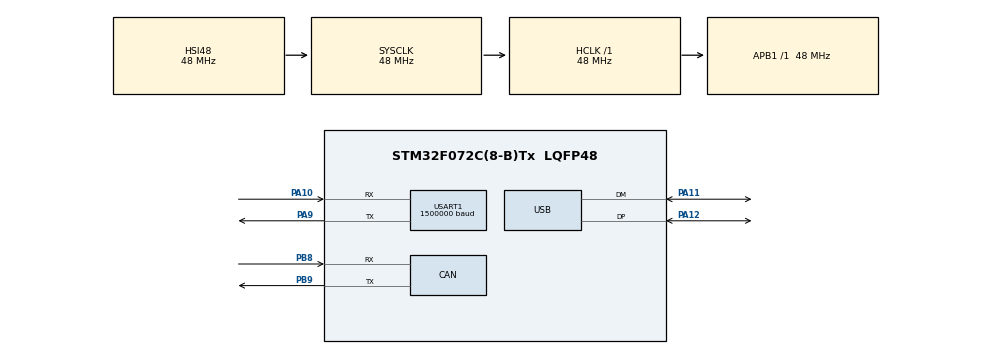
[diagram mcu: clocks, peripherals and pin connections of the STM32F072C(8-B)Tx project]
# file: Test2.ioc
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CAN.CalculateTimeQuantum=333.3333333333333
Mcu.Family=STM32F0
Mcu.Name=STM32F072C(8-B)Tx
Mcu.Package=LQFP48
NVIC.USB_IRQn=true\:0\:0\:false\:false\:true\:false\:true
PA10.Mode=Asynchronous
PA10.Signal=USART1_RX
PA11.Mode=Device
PA11.Signal=USB_DM
PA12.Mode=Device
PA12.Signal=USB_DP
PA9.Mode=Asynchronous
PA9.Signal=USART1_TX
PB8.Mode=Master
PB8.Signal=CAN_RX
PB9.Mode=Master
PB9.Signal=CAN_TX
ProjectManager.HeapSize=0x200
ProjectManager.StackSize=0x400
ProjectManager.TargetToolchain=STM32CubeIDE
RCC.AHBFreq_Value=48000000
RCC.APB1Freq_Value=48000000
RCC.APB1TimFreq_Value=48000000
RCC.HCLKFreq_Value=48000000
RCC.SYSCLKFreq_VALUE=48000000
RCC.SYSCLKSource=RCC_SYSCLKSOURCE_HSI48
USART1.BaudRate=1500000
USART1.VirtualMode-Asynchronous=VM_ASYNC
USB_DEVICE.CLASS_NAME_FS=HID
USB_DEVICE.PID_HID_FS=0x572c
USB_DEVICE.VID=0x483
USB_DEVICE.VirtualMode=Hid
USB_DEVICE.VirtualModeFS=Hid_FS
VP_USB_DEVICE_VS_USB_DEVICE_HID_FS.Mode=HID_FS
board=custom

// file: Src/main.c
/* USER CODE BEGIN Header */
/**
  ******************************************************************************
  * @file           : main.c
  * @brief          : Main program body
  ******************************************************************************
  * @attention
  *
  * <h2><center>&copy; Copyright (c) 2019 STMicroelectronics.
  * All rights reserved.</center></h2>
  *
  * This software component is licensed by ST under BSD 3-Clause license,
  * the "License"; You may not use this file except in compliance with the
  * License. You may obtain a copy of the License at:
  *                        opensource.org/licenses/BSD-3-Clause
  *
  ******************************************************************************
  */
/* USER CODE END Header */

#include "main.h"
#include "usb_device.h"

/* USER CODE BEGIN Includes */
#include "debug_comm.h"
/* USER CODE END Includes */

CAN_HandleTypeDef hcan;

UART_HandleTypeDef huart1;

void SystemClock_Config(void);
static void MX_GPIO_Init(void);
static void MX_CAN_Init(void);
static void MX_USART1_UART_Init(void);

int main(void)
{

  /* MCU Configuration--------------------------------------------------------*/

  /* Reset of all peripherals, Initializes the Flash interface and the Systick. */
  HAL_Init();

  /* Configure the system clock */
  SystemClock_Config();

  /* Initialize all configured peripherals */
  MX_GPIO_Init();
  MX_CAN_Init();
  MX_USART1_UART_Init();
  MX_USB_DEVICE_Init();

  /* Infinite loop */
  while (1)
  {

  }
}

void SystemClock_Config(void)
{
  RCC_OscInitTypeDef RCC_OscInitStruct = {0};
  RCC_ClkInitTypeDef RCC_ClkInitStruct = {0};
  RCC_PeriphCLKInitTypeDef PeriphClkInit = {0};

  /** Initializes the CPU, AHB and APB busses clocks
  */
  RCC_OscInitStruct.OscillatorType = RCC_OSCILLATORTYPE_HSI48;
  RCC_OscInitStruct.HSI48State = RCC_HSI48_ON;
  RCC_OscInitStruct.PLL.PLLState = RCC_PLL_NONE;
  if (HAL_RCC_OscConfig(&RCC_OscInitStruct) != HAL_OK)
  {
    Error_Handler();
  }
  /** Initializes the CPU, AHB and APB busses clocks
  */
  RCC_ClkInitStruct.ClockType = RCC_CLOCKTYPE_HCLK|RCC_CLOCKTYPE_SYSCLK
                              |RCC_CLOCKTYPE_PCLK1;
  RCC_ClkInitStruct.SYSCLKSource = RCC_SYSCLKSOURCE_HSI48;
  RCC_ClkInitStruct.AHBCLKDivider = RCC_SYSCLK_DIV1;
  RCC_ClkInitStruct.APB1CLKDivider = RCC_HCLK_DIV1;

  if (HAL_RCC_ClockConfig(&RCC_ClkInitStruct, FLASH_LATENCY_1) != HAL_OK)
  {
    Error_Handler();
  }
  PeriphClkInit.PeriphClockSelection = RCC_PERIPHCLK_USB|RCC_PERIPHCLK_USART1;
  PeriphClkInit.Usart1ClockSelection = RCC_USART1CLKSOURCE_PCLK1;
  PeriphClkInit.UsbClockSelection = RCC_USBCLKSOURCE_HSI48;

  if (HAL_RCCEx_PeriphCLKConfig(&PeriphClkInit) != HAL_OK)
  {
    Error_Handler();
  }
}

static void MX_CAN_Init(void)
{

  hcan.Instance = CAN;
  hcan.Init.Prescaler = 16;
  hcan.Init.Mode = CAN_MODE_NORMAL;
  hcan.Init.SyncJumpWidth = CAN_SJW_1TQ;
  hcan.Init.TimeSeg1 = CAN_BS1_1TQ;
  hcan.Init.TimeSeg2 = CAN_BS2_1TQ;
  hcan.Init.TimeTriggeredMode = DISABLE;
  hcan.Init.AutoBusOff = DISABLE;
  hcan.Init.AutoWakeUp = DISABLE;
  hcan.Init.AutoRetransmission = DISABLE;
  hcan.Init.ReceiveFifoLocked = DISABLE;
  hcan.Init.TransmitFifoPriority = DISABLE;
  if (HAL_CAN_Init(&hcan) != HAL_OK)
  {
    Error_Handler();
  }

}

static void MX_USART1_UART_Init(void)
{

  huart1.Instance = USART1;
  huart1.Init.BaudRate = 1500000;
  huart1.Init.WordLength = UART_WORDLENGTH_8B;
  huart1.Init.StopBits = UART_STOPBITS_1;
  huart1.Init.Parity = UART_PARITY_NONE;
  huart1.Init.Mode = UART_MODE_TX_RX;
  huart1.Init.HwFlowCtl = UART_HWCONTROL_NONE;
  huart1.Init.OverSampling = UART_OVERSAMPLING_16;
  huart1.Init.OneBitSampling = UART_ONE_BIT_SAMPLE_DISABLE;
  huart1.AdvancedInit.AdvFeatureInit = UART_ADVFEATURE_NO_INIT;
  if (HAL_UART_Init(&huart1) != HAL_OK)
  {
    Error_Handler();
  }

}

static void MX_GPIO_Init(void)
{

  /* GPIO Ports Clock Enable */
  __HAL_RCC_GPIOA_CLK_ENABLE();
  __HAL_RCC_GPIOB_CLK_ENABLE();

}

void Error_Handler(void)
{
}

/************************ (C) COPYRIGHT STMicroelectronics *****END OF FILE****/
